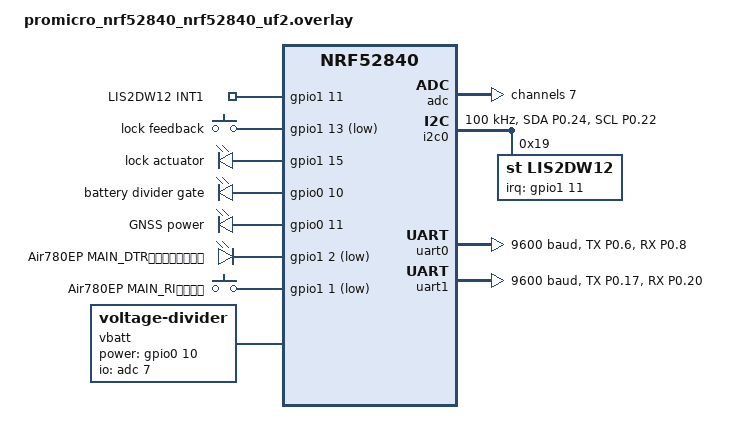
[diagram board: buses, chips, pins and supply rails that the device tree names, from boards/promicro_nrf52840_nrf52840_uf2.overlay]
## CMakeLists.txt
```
# 电瓶车定位固件（nRF52840 / NCS-Zephyr）
#
# ⚠ 本文件在写入时**没有被编译验证过** —— 这台机器上没有 NCS/Zephyr SDK，
#    也没有任何 C 编译器（`gcc: command not found`）。语法与 API 用法是按
#    DESIGN.md 里已核实的符号名写的，但**第一次 `west build` 一定会有编译错误**。
#    见 docs/FIRMWARE.md 的「怎么编译」一节。

cmake_minimum_required(VERSION 3.20.0)

find_package(Zephyr REQUIRED HINTS $ENV{ZEPHYR_BASE})
project(ebike_tracker C)

target_sources(app PRIVATE
    src/main.c
    src/proto.c
    src/nvstore.c
    src/crypto.c
    src/unlock.c
    src/ble_unlock.c
    src/motion.c
    src/battery.c
    src/lock.c
    src/gnss.c
    src/modem.c
    src/uplink.c
)

target_include_directories(app PRIVATE src)
```

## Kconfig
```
menu "电瓶车定位固件"

config EBIKE_DEVICE_ID
	string "设备 id（等于 MQTT 用户名，出现在 topic 层级里）"
	default "bike01"
	help
	  必须匹配 [a-z0-9-]{1,32}，且服务端配置里要有同名设备。
	  契约 §4：id 在 topic 层级里，ACL 靠前缀隔离。

config EBIKE_FW_VERSION
	string "固件版本（上报在 up/hello 的 fw 字段）"
	default "0.1.0"

config EBIKE_MQTT_HOST
	string "MQTT 服务端主机名或 IP"
	default "192.168.1.10"
	help
	  必须与服务端证书的 CN 一致 —— 模组的 AT+SSLCFG="hostname" 会校验它。
	  填错的话设备侧只会看到一个 ERROR，隔着 9600 baud 极难诊断。

config EBIKE_MQTT_PORT
	int "MQTT 端口"
	default 8883

config EBIKE_MQTT_PASSWORD
	string "MQTT 口令"
	default ""
	help
	  由服务端的 `ebike-server init` 生成，只显示一次。
	  ⚠ 这个值会明文进固件二进制。设备装在车上，拆开就能读 flash
	  （DESIGN.md §5.4 第 1 条已承认这个攻击面），所以它和客户端证书
	  私钥的安全等级一样 —— 这正是契约 §2 决定不做 mTLS 的理由。

config EBIKE_REPORT_INTERVAL
	int "默认上报周期（秒）"
	default 900
	help
	  服务端的离线判定 = 本值 × 3 + 120（契约 §4.2），
	  改这里要同时改服务端配置的 report_interval。

config EBIKE_MOTION_THRESHOLD_MG
	int "运动唤醒阈值（mg）"
	default 150
	range 31 2000
	help
	  LIS2DW12 的 WAKE_UP_THS 一格 = 31.25 mg（±2 g 量程）。
	  电瓶车从 100~200 mg 起调（DESIGN.md §3.7）。
	  阈值只能运行时设，不是 DTS 属性。

config EBIKE_STILL_AFTER_S
	int "多久没有运动事件就判静止（秒）"
	default 30
	range 5 600
	help
	  软件静止判定的超时。**硬件的 STATIONARY 事件在本板上用不了**
	  （走 INT2，只接了 INT1），所以静止完全靠这个计时器 ——
	  详见 src/motion.h 的长注释。

	  必须明显小于 main.c 的 IDLE_AFTER_STILL_MS（5 分钟，关广播的门槛）：
	  前者判「不动了」，后者判「不动够久了」。设得比它大的话关广播的条件
	  永远等不到。motion.c 里有 BUILD_ASSERT 钉这一条。

	  30 秒的取值：等红灯、推车挪位这类停顿不该立刻判成静止，
	  但也不能久到让「车被搬走后又静止了」这个事件迟迟不上报。

config EBIKE_LOW_VOLT_1
	int "第一欠压阈值（毫伏）"
	default 46000
	help
	  跨过就降低上报频率并报 lowbatt lv=1（DESIGN.md §6）。
	  具体值依赖实际电池组的 BMS 截止点，采购后实测确定。

config EBIKE_LOW_VOLT_2
	int "第二欠压阈值（毫伏）"
	default 44000
	help
	  跨过就停止周期上报，只保留手机 BLE 开锁（那条路完全离线，不吃车电池
	  的通信开销）。运动事件仍然会触发一次上报 —— 车在这个电量下被动了，
	  比省那点电重要。

config EBIKE_LOW_VOLT_3
	int "第三欠压阈值（毫伏）"
	default 42000
	help
	  跨过就主动进 System OFF，只留运动唤醒（DESIGN.md §6 第 4 级）。
	  这一级是保护**车电池**不被抽空，不是保护设备自己（设备没有独立电源）。
	  42 V 是 48 V 铅酸 12 节 × 1.75 V/节 的物理底线；锂电要按 BMS 截止点改。
	  必须 < LOW_VOLT_2，否则第 2 级永远不会生效。

config EBIKE_ALLOW_REMOTE_UNLOCK
	bool "接受下行的 unlock 指令"
	default n
	help
	  远程开锁绕过 §5.2 的挑战应答，信的只是 MQTT 那层的 TLS + 口令。
	  服务端侧默认也是关的（契约 §6.1），两边都要打开才生效。

config EBIKE_LOG_LEVEL
	int "本项目模块的日志等级"
	default 3
	range 0 4

endmenu

source "Kconfig.zephyr"
```

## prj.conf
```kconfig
# nRF52840 ProMicro 克隆板 —— 电瓶车定位 + 手机 BLE 开锁
#
# 符号名的两处更正来自 DESIGN.md §2.2，原稿写错过：
#   CONFIG_PSA_WANT_KEY_TYPE_HMAC（不是 KEY_TYPE_AES）
# DTS 里的 irq-gpios（不是 int1-gpios）见 overlay。

# --- 板级 / 构建 ---------------------------------------------------------------
# 板子自带 Adafruit bootloader，**不要用 MCUboot**（DESIGN.md §3.4：会打架）
CONFIG_USE_DT_CODE_PARTITION=y
CONFIG_BUILD_OUTPUT_UF2=y

# --- BLE（GATT peripheral，开锁通道） -----------------------------------------
# 手机当 central 写 APDU，车回 notify —— DESIGN.md §2.1。
# 只做 peripheral：本设备从不主动扫描或发起连接。
CONFIG_BT=y
CONFIG_BT_PERIPHERAL=y
CONFIG_BT_MAX_CONN=1
CONFIG_BT_DEVICE_NAME="ebike"

# **不开 SMP、不开 BT_SETTINGS**，这是有意的（DESIGN.md §5.5 / ADR-004 §5）：
# 设备没有屏幕也没有键盘，IO capability 只能是 NoInputNoOutput，
# 那种配置下 LESC 只能走 Just Works —— 没有 MITM 防护（host/smp.c 的
# remote_sec_level_reachable() 对 JUST_WORKS 直接返回 AUTH_REQUIREMENTS，
# L3/L4 达不到）。认证由 §5.2 的 HMAC 挑战应答负责，不依赖链路加密。
# 不开 SMP ⇒ 没有 LTK/IRK 要持久化 ⇒ 不该让 BT 去写 counter 住的那 32 kB
# storage 分区（BT_SETTINGS 还会让 settings_load 多一处时序要求）。
CONFIG_BT_SMP=n
CONFIG_BT_SETTINGS=n

# MTU 必须调大，默认值差得不止一点：
#   ATT_MTU 默认 23（host/att_internal.h 的 BT_ATT_DEFAULT_LE_MTU），
#   写请求可写载荷 = ATT_MTU − 3（1 B opcode + 2 B handle）= 20 字节，
#   而最长一条 C-APDU 是 UNLOCK：5 + [uid(4)+counter(4)+mac(16)] + 1 = 30 字节。
# 本地上限由两者取小决定（att_internal.h：MIN(BT_L2CAP_RX_MTU, BT_L2CAP_TX_MTU)，
# 其中 BT_L2CAP_RX_MTU = CONFIG_BT_BUF_ACL_RX_SIZE − 4），所以两个都要给：
#   40 − 3 = 37 ≥ 30 ✓        44 − 4 = 40 ≥ 40 ✓
# ⚠ 副作用：ACL_RX_SIZE > 27 会让 BT_DATA_LEN_UPDATE 变成 default y，
#   进而 BT_CTLR_DATA_LENGTH=y，SDC 的 per-link 缓冲跟着涨。这是划算的 ——
#   换掉的是应用层分包逻辑，而分包会让「nonce 一次性」的安全论证被半条报文复杂化。
# ⚠ 手机侧仍要主动 requestMtu()：MTU 交换由 central 发起，我们是 server，
#   CONFIG_BT_GATT_AUTO_UPDATE_MTU 只对 GATT client 有效。
CONFIG_BT_L2CAP_TX_MTU=40
CONFIG_BT_BUF_ACL_RX_SIZE=44

# --- 密码学（CryptoCell-310 硬件 HMAC） ----------------------------------------
CONFIG_PSA_CRYPTO=y
CONFIG_PSA_WANT_GENERATE_RANDOM=y
CONFIG_PSA_WANT_ALG_HMAC=y
CONFIG_PSA_WANT_ALG_SHA_256=y
CONFIG_PSA_WANT_KEY_TYPE_HMAC=y
CONFIG_PSA_CRYPTO_DRIVER_CC3XX=y

# --- 持久化（密钥、counter、序号 q） -------------------------------------------
# counter 掉电必须不回零，否则 §5.2 的重放防护失效
CONFIG_SETTINGS=y
CONFIG_SETTINGS_NVS=y
CONFIG_NVS=y
CONFIG_FLASH=y
CONFIG_FLASH_MAP=y
CONFIG_FLASH_PAGE_LAYOUT=y

# --- 传感器 -------------------------------------------------------------------
CONFIG_SENSOR=y
CONFIG_LIS2DW12=y
CONFIG_LIS2DW12_TRIGGER_OWN_THREAD=y
CONFIG_LIS2DW12_THREAD_STACK_SIZE=1024

# `CONFIG_LIS2DW12_WAKEUP` 必须开，它 gate 了两样东西：
#   1. `SENSOR_TRIG_MOTION`（驱动的 `case SENSOR_TRIG_MOTION` 整段裹在
#      `#ifdef CONFIG_LIS2DW12_WAKEUP` 里，不开的话 sensor_trigger_set
#      返回 -ENOTSUP，motion_init 直接失败 —— **唤醒源根本不存在**）；
#   2. `SENSOR_ATTR_UPPER_THRESH`（lis2dw12.c:322 的
#      `#if (CONFIG_LIS2DW12_SLEEP || CONFIG_LIS2DW12_WAKEUP)`）—— 是 `||`，
#      所以单开 WAKEUP 就够，阈值照样能设。
CONFIG_LIS2DW12_WAKEUP=y

# ⚠ **`CONFIG_LIS2DW12_SLEEP` 刻意不开**（原来是 `=y`）。
# 它只 gate `SENSOR_TRIG_STATIONARY`，而那个触发走 **INT2**，本板只接了 INT1
# —— 注册它会返回 0 但事件永不到达（src/motion.h 的长注释）。
# 静止判定已改成 motion.c 里的软件计时（`CONFIG_EBIKE_STILL_AFTER_S`），
# 代码里不再注册 STATIONARY，所以这个符号是纯负担：
# 多编一段 ISR 分支、多一个 handler 指针、还让读配置的人以为硬件静止检测可用。

CONFIG_I2C=y
CONFIG_ADC=y
CONFIG_GPIO=y

# ⚠ **必须显式关掉。** overlay 里 `vbatt` 节点的 compatible 是 "voltage-divider"，
# 而 `drivers/sensor/voltage_divider/Kconfig` 是 `default y` +
# `depends on DT_HAS_VOLTAGE_DIVIDER_ENABLED` —— 只要节点存在它就会被编进来。
#
# 那个驱动会成为 `power-gpios`（= batt_gate）的**第二个占有者**，而且默认状态相反：
# `voltage_init()` 结尾的 `pm_device_driver_init()` 在 PM_DEVICE=y /
# PM_DEVICE_RUNTIME=n 下会依次跑 TURN_ON → **RESUME**，RESUME 里
# `gpio_pin_set_dt(&config->gpio_power, 1)` 把门控**打开并一直留着**。
# 现在只是因为 `battery_init()` 在 application 阶段跑得更晚、又把它拉回低
# 才没事 —— 依赖初始化顺序的巧合，不是设计。
#
# battery.c 用到的两样东西都不需要这个驱动：
#   VOLTAGE_DIVIDER_DT_SPEC_GET  —— 纯 DT 宏
#   voltage_divider_scale_dt()   —— 头文件里的 static inline
# 所以关掉它没有任何损失，只去掉一个会偷偷开门控的所有者。
CONFIG_VOLTAGE_DIVIDER=n

# --- 串口（GNSS + Air780EP） ---------------------------------------------------
CONFIG_SERIAL=y
CONFIG_UART_INTERRUPT_DRIVEN=y
CONFIG_UART_ASYNC_API=n
CONFIG_RING_BUFFER=y

# --- 低功耗 -------------------------------------------------------------------
# System OFF 0.40 µA / System ON+RTC 3.16 µA（DESIGN.md §4.2）
#
# ⚠ **不要加 CONFIG_PM=y。** `subsys/pm/Kconfig` 的 `config PM` 要求
# `depends on SYS_CLOCK_EXISTS && HAS_PM`，而 `soc/nordic/nrf52/Kconfig` 只
# `select HAS_POWEROFF`，**没有 HAS_PM**（整棵树里 select HAS_PM 的只有
# nrf54h / nrf92）。写了会是未满足依赖的 Kconfig warning，而 Zephyr 的
# `scripts/kconfig/kconfig.py` 把这类 warning 升级成 error。
# 上游的 `samples/boards/nordic/system_off` 也只开 PM_DEVICE + POWEROFF。
CONFIG_PM_DEVICE=y
CONFIG_POWEROFF=y

# --- 日志：走 RTT，不走 UART/USB ------------------------------------------------
# 板级默认（`boards/common/usb/Kconfig.cdc_acm_serial.defconfig`）会把 console
# 挂到 **USB CDC ACM**（`cdc_acm_serial.dtsi` 里 `zephyr,console = &board_cdc_acm_uart`），
# 并且 `CDC_ACM_SERIAL_INITIALIZE_AT_BOOT` 默认 y —— 那意味着开机就起 USB 栈。
# 电池产品不能这样：USB 外设常开是毫安级，而且本设计的 USB 口根本不引出（§5.9）。
#
# 所以关掉板级 CDC ACM 后端，改用 RTT：RTT 在没接调试器时不产生额外功耗，
# 而 J-Link 仍然是这块克隆板的调试主路（板载 bootloader 只给 UF2 烧写，
# 单步和实时日志都要 SWD）。
# 顺带解掉一个隐患：console 若落到 uart0，会和 GNSS 抢同一个外设。
CONFIG_BOARD_SERIAL_BACKEND_CDC_ACM=n
CONFIG_USE_SEGGER_RTT=y
CONFIG_RTT_CONSOLE=y
CONFIG_UART_CONSOLE=n
CONFIG_CONSOLE=y
CONFIG_LOG=y
CONFIG_LOG_MODE_DEFERRED=y
CONFIG_LOG_BACKEND_RTT=y
CONFIG_LOG_DEFAULT_LEVEL=3

# --- 其它 ---------------------------------------------------------------------
CONFIG_MAIN_STACK_SIZE=4096
CONFIG_REBOOT=y
# 复位原因 → 契约 §5.1 的 rst 五值闭集（uplink.c 的 reset_cause_str）。
# ⚠ `CONFIG_HWINFO` 这一行**必须有**：`drivers/hwinfo/Kconfig.nrf` 是
# rsource 在 `if HWINFO` 里的，所以 `HWINFO_NRF` 的那个 `default y`
# 只有在 HWINFO 打开之后才生效。少这一行是链接期
# `undefined reference to z_impl_hwinfo_get_reset_cause`（实测过）。
CONFIG_HWINFO=y
CONFIG_JSON_LIBRARY=n
# proto.c 用 base64_decode() 解 dn/secret 的 32 字节密钥（契约 §6.2）。
# 这个符号默认 n，不开就是链接期 `undefined reference to base64_decode`（实测过）。
CONFIG_BASE64=y
# proto.c 用 %.6f / %.1f 拼报文，没有它坐标会变成乱码
CONFIG_CBPRINTF_FP_SUPPORT=y
```

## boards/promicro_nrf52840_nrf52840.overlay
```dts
/*
 * 板级 overlay：nRF52840 ProMicro 克隆板。
 *
 * ⚠ 两处必须自己确认的（DESIGN.md §3.4 / §3.5）：
 *
 * 1. **pinctrl 冲突**：上游 promicro_nrf52840-pinctrl.dtsi 的 uart0 是
 *    TX=P0.09 / RX=P0.10，而这两个脚是 NFC1/NFC2。下面把 uart0 挪到
 *    P0.06/P0.08，并新开 uart1 给 Air780EP。**引脚号是按 J2/J4 的可用脚挑的，
 *    实物到手要对着板子核一遍。**
 *
 * 2. **GPIO 余量是 19 个**（21 可用 − NFCT 占 2）。下面用掉 17 个。
 *    如果锁要 3 根线，就是 19/19 零余量，INT2 那根潜在的第二中断线没地方接。
 */

/ {
	aliases {
		/* ⚠ **只保留真正被 DT_ALIAS 取用的那一个。**
		 * 其余六个（lock-drive / lock-sense / batt-gate / gnss-power /
		 * modem-pwrkey / modem-ri）删掉了：所有 .c 文件一律用
		 * `DT_NODELABEL(...)`，那些别名是纯装饰，留着只会让人以为
		 * 换引脚时改别名就够了。
		 *
		 * `motion-int` 留着是因为 main.c 的 `enter_system_off()` 用
		 * `DT_ALIAS(motion_int)` 拿这根线 —— 它要绕过 LIS2DW12 驱动
		 * 自己把触发方式从边沿改成 level sense（GPIOTE 在 System OFF
		 * 下断电，只有 SENSE→DETECT 能唤醒）。 */
		motion-int = &motion_int;
	};

	ebike_gpios {
		compatible = "gpio-keys";

		/* LIS2DW12 INT1。
		 * ⚠ **这个节点和 `&lis2dw12` 的 `irq-gpios` 是同一根物理线**
		 * （都是 P1.11）。两处声明是故意的、也是必需的：
		 * 传感器驱动按边沿触发配它（`GPIO_INT_EDGE_TO_ACTIVE`），
		 * 而进 System OFF 前应用层必须把它重配成 level sense
		 * （见 main.c 的 `enter_system_off()`）—— 那需要一个
		 * 独立于传感器驱动的 `gpio_dt_spec`，就是这个节点。
		 *
		 * `gpio-keys` 只是借用一个通用的 GPIO 容器 binding；
		 * `CONFIG_GPIO_KEYS` 没开，所以上游 gpio_keys 驱动不会实例化它。
		 *
		 * 传感器侧必须配成推挽高有效 —— 开漏+上拉会让引脚停在
		 * VIL/VIH 之间，nRF52840 手册明确说那会增加电流（DESIGN.md §3.7），
		 * 而且悬空电平会让 level sense 反复自触发。 */
		motion_int: motion_int {
			gpios = <&gpio1 11 (GPIO_ACTIVE_HIGH | GPIO_PULL_DOWN)>;
			label = "LIS2DW12 INT1";
		};

		/* 锁位置反馈微动开关 */
		lock_sense: lock_sense {
			gpios = <&gpio1 13 (GPIO_ACTIVE_LOW | GPIO_PULL_UP)>;
			label = "lock feedback";
		};
	};

	ebike_outputs {
		compatible = "gpio-leds";

		/* 锁驱动。电磁锁 vs 电机锁还没定（DESIGN.md §7 第 1 条），
		 * 这里按「一根线，高有效，脉冲驱动」写，定了之后可能要改成半桥两根线。 */
		lock_drive: lock_drive {
			gpios = <&gpio1 15 GPIO_ACTIVE_HIGH>;
			label = "lock actuator";
		};

		/* 电池采样分压的门控 MOSFET。1M+1M 分压对 58.8V 是 29 µA 常流，
		 * 比整机静态电流大一个量级，所以只在测的瞬间开（DESIGN.md §3.6）。 */
		batt_gate: batt_gate {
			gpios = <&gpio0 4 GPIO_ACTIVE_HIGH>;
			label = "battery divider gate";
		};

		/* GNSS 电源门控。开关管型号未定（DESIGN.md §7.2）。 */
		gnss_power: gnss_power {
			gpios = <&gpio0 11 GPIO_ACTIVE_HIGH>;
			label = "GNSS power";
		};

		/* Air780EP PWRKEY：开集拉低 >1 s 开机。
		 * ⚠ 模组内部已有 5.6k 上拉，**不要外加上拉**（DESIGN.md §8.1）。
		 * 模组上电不自启动，所以这根线是必须的。 */
		modem_pwrkey: modem_pwrkey {
			gpios = <&gpio0 12 GPIO_ACTIVE_LOW>;
			label = "Air780EP PWRKEY";
		};
	};

	ebike_inputs {
		compatible = "gpio-keys";

		/* MAIN_RI：AT+CFGRI=1 之后出 120 ms 低脉冲。
		 * ⚠ 必须配 AT^WAKEUPHEX 把 RI 限定到魔术下行串，否则每条例行 URC
		 * 都会把主控从 System OFF 拽出来，功耗预算直接崩（DESIGN.md §8.3）。
		 * ⚠⚠ 这两条命令在 AT 固件 V1011 上能不能用**未核实**（§8.7），
		 * R0 阶段用一根 UART 线先验。
		 *
		 * ⚠⚠⚠ **两件事都还没落地，这个节点目前只是声明**：
		 * 1. P0.26 是**占位脚号**（DESIGN.md §11 #18）。真实的 MAIN_RI
		 *    脚号至今无来源（`docs.openluat.com/4Gmodulepin/` 404），
		 *    **布板前必须查 `Air780EP硬件手册V1.1.pdf`**。
		 * 2. **没有任何 C 代码取用它**（全 src 搜 `modem_ri` 只有这里）。
		 *    modem.c 发了 `AT+CFGRI=1`，但主控侧没人监听这根线 ——
		 *    「模组主动唤醒主控」这条链目前是半条。
		 *    定完脚号之后还要写监听代码。 */
		modem_ri: modem_ri {
			gpios = <&gpio0 26 (GPIO_ACTIVE_LOW | GPIO_PULL_UP)>;
			label = "Air780EP MAIN_RI (占位脚号，无代码取用)";
		};
	};

	/* 电池电压采样。ADC 只有 3 个真脚（DESIGN.md §3.5）：
	 * P0.02(AIN0) / P0.29(AIN5) / P0.31(AIN7)。用 P0.31。
	 * ZMK 的 A6~A10 别名不是 SAADC 通道，别当模拟脚用。 */
	vbatt: vbatt {
		compatible = "voltage-divider";
		io-channels = <&adc 7>;
		output-ohms = <1000000>;
		full-ohms = <2000000>;
		power-gpios = <&gpio0 4 GPIO_ACTIVE_HIGH>;
	};
};

&adc {
	status = "okay";
	#address-cells = <1>;
	#size-cells = <0>;

	channel@7 {
		reg = <7>;
		zephyr,gain = "ADC_GAIN_1_6";
		zephyr,reference = "ADC_REF_INTERNAL";
		zephyr,acquisition-time = <ADC_ACQ_TIME(ADC_ACQ_TIME_MICROSECONDS, 40)>;
		zephyr,input-positive = <NRF_SAADC_AIN7>;
		zephyr,resolution = <12>;
	};
};

/* --- I2C：LIS2DW12 ---------------------------------------------------------
 * 地址 0x19 要求 SA0/SDO 接 VDD_IO。
 * ⚠ SA0 接地的话内部 20.4~54.4 kΩ 上拉会白烧 110~160 µA（DESIGN.md §3.7）。
 */
&i2c0 {
	status = "okay";
	compatible = "nordic,nrf-twim";
	clock-frequency = <I2C_BITRATE_STANDARD>;
	pinctrl-0 = <&i2c0_default>;
	pinctrl-1 = <&i2c0_sleep>;
	pinctrl-names = "default", "sleep";

	lis2dw12: lis2dw12@19 {
		compatible = "st,lis2dw12";
		reg = <0x19>;
		irq-gpios = <&gpio1 11 GPIO_ACTIVE_HIGH>;   /* 属性名是 irq-gpios */
		int-pin = <1>;
		odr = <12>;                  /* 12.5 Hz → 1 µA @LP mode 1 */
		range = <2>;                 /* ±2 g，阈值一格 31.25 mg */
		power-mode = <LIS2DW12_DT_LP_M1>;
		wakeup-duration = <LIS2DW12_DT_WAKEUP_2_ODR>;
	};
};

/* --- UART0：GNSS（ATGM336H-5N，NMEA 9600） --------------------------------- */
&uart0 {
	status = "okay";
	current-speed = <9600>;
	pinctrl-0 = <&uart0_default>;
	pinctrl-1 = <&uart0_sleep>;
	pinctrl-names = "default", "sleep";
};

/* --- UART1：Air780EP AT 链路 -----------------------------------------------
 * 9600 锁死：AT+IPR 默认自适应太脆，而两种低功耗模式都要求 9600
 * 才能可靠唤醒（DESIGN.md §8.1）。出厂 AT+IPR=9600;&W 设一次。
 */
&uart1 {
	status = "okay";
	current-speed = <9600>;
	pinctrl-0 = <&uart1_default>;
	pinctrl-1 = <&uart1_sleep>;
	pinctrl-names = "default", "sleep";
};

&pinctrl {
	/* ⚠ 把 uart0 从 P0.09/P0.10 挪开 —— 那两个脚给 NFCT 了。
	 * 上游 promicro_nrf52840-pinctrl.dtsi 的默认值会和 NFC 撞（DESIGN.md §3.4）。 */
	uart0_default: uart0_default {
		group1 {
			psels = <NRF_PSEL(UART_TX, 0, 6)>;
		};
		group2 {
			psels = <NRF_PSEL(UART_RX, 0, 8)>;
			bias-pull-up;
		};
	};

	uart0_sleep: uart0_sleep {
		group1 {
			psels = <NRF_PSEL(UART_TX, 0, 6)>,
				<NRF_PSEL(UART_RX, 0, 8)>;
			low-power-enable;
		};
	};

	uart1_default: uart1_default {
		group1 {
			psels = <NRF_PSEL(UART_TX, 0, 17)>;
		};
		group2 {
			psels = <NRF_PSEL(UART_RX, 0, 20)>;
			bias-pull-up;
		};
	};

	uart1_sleep: uart1_sleep {
		group1 {
			psels = <NRF_PSEL(UART_TX, 0, 17)>,
				<NRF_PSEL(UART_RX, 0, 20)>;
			low-power-enable;
		};
	};

	i2c0_default: i2c0_default {
		group1 {
			psels = <NRF_PSEL(TWIM_SDA, 0, 24)>,
				<NRF_PSEL(TWIM_SCL, 0, 22)>;
		};
	};

	i2c0_sleep: i2c0_sleep {
		group1 {
			psels = <NRF_PSEL(TWIM_SDA, 0, 24)>,
				<NRF_PSEL(TWIM_SCL, 0, 22)>;
			low-power-enable;
		};
	};
};

/* SPI1 在 ZMK 的默认 pinctrl 里把 MOSI 放在 P0.10 —— 和 NFC2 撞，关掉。 */
&spi1 {
	status = "disabled";
};
```

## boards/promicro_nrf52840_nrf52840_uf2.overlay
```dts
/*
 * 板级 overlay：nRF52840 ProMicro 克隆板。
 *
 * ⚠ 三件必须对着实物/netlist 核的事（DESIGN.md §3.4 / §3.5）：
 *
 * 1. **只能用引出到排针的脚。** SoC 有 48 个 GPIO，这块板子只把 **21 个**
 *    引到焊盘，其余的**只到芯片焊盘、哪儿都不通** —— 而 devicetree 对此
 *    一无所知，填一个没引出的脚**编译照过**，直到接线时才发现没地方接。
 *    这个坑已经踩过三次（P0.04 门控、P0.12 PWRKEY、P0.26 RI，都在
 *    2026-09-04 从 `sasodoma/nrf52840-promicro` 的 netlist 逐脚复核时抓到）。
 *
 *    **引出脚白名单**（逐个 pad 追 net → 元件焊盘数出来的）：
 *      J2 十个：P0.06 P0.08 P0.17 P0.20 P0.22 P0.24 P1.00 P0.11 P1.04 P1.06
 *      J3 八个：P0.09 P0.10 P1.11 P1.13 P1.15 P0.02 P0.29 P0.31
 *      J4 三个：P1.01 P1.02 P1.07
 *    板内占用不引出：P0.00/P0.01（Y2 晶振）、P0.13（ME6217 CE）、P0.15（蓝 LED）。
 *    J3 第 10 个焊盘是 RESET（UICR.PSELRESET = P0.18），不能当 GPIO 用。
 *    `server/tests/test_firmware_contract.py` 把这份白名单钉成断言。
 *
 * 2. **pinctrl 冲突**：上游 promicro_nrf52840-pinctrl.dtsi 的 uart0 是
 *    TX=P0.09 / RX=P0.10。下面把 uart0 挪到 P0.06/P0.08，并新开 uart1
 *    给 Air780EP。
 *    （挪开的原始理由是 P0.09/P0.10 要给 NFCT；开锁改走 BLE 之后那两个脚
 *    自由了，其中 P0.10 现在给了 `batt_gate`，P0.09 是余量。）
 *
 * 3. **上游板级 DTS 会悄悄抢走排针脚**，文件末尾统一关掉：
 *    `i2c1`（P1.04/P1.06 = J2.12/J2.13）、`spi2`（P1.01/P1.02/P1.07 = 整个 J4）。
 *    i2c1 尤其阴险：`CONFIG_I2C_NRFX_TWIM=y` 让 twim1 真的实例化，
 *    `pm_device_driver_init()` 的 RESUME 会 `pinctrl_apply_state(DEFAULT)`，
 *    **开机就把那两个脚配成 I2C**（ELF 里 `__device_dts_ord_73` 实测存在）。
 *    ⚠ spi2 关掉这件事现在是**必需**而不是预防：`modem_ri`/`modem_dtr` 用了
 *    P1.01/P1.02，正是 spi2 的默认 SCK/MOSI。
 *
 * 用掉 14 个（下面逐个数），余 7 个：P0.02 P0.09 P0.29 P1.00 P1.04 P1.06 P1.07。
 * 锁要 3 根线、INT2 那根第二中断线都装得下。
 *
 * 2026-09-04 第二次改动（PWRKEY 已在硬件上接地）：
 *   `modem_pwrkey` P1.00 → **节点删除**（驱动一个已接地的脚 = 短路，见下面
 *   那段长注释）；新增 `modem_ri` P1.01（直连）、`modem_dtr` P1.02（开漏）。
 *   净变化：用掉的脚 13 → 14，P1.00 回到余量池。
 */

/* `power-mode` / `wakeup-duration` 用的是 LIS2DW12 的 dt-bindings 宏，
 * 而板级 DTS 不会带进这个头 —— 不显式 include 就是一个
 * 「expected number or parenthesized expression」的 devicetree parse error。
 * 其余宏（GPIO_ACTIVE_*、NRF_PSEL、NRF_SAADC_*、I2C_BITRATE_*）由
 * 板级 DTS / SoC dtsi 一路带进来，不用再 include。 */
#include <zephyr/dt-bindings/sensor/lis2dw12.h>

/ {
	aliases {
		/* ⚠ **只保留真正被 DT_ALIAS 取用的那一个。**
		 * 其余五个（lock-drive / lock-sense / batt-gate / gnss-power /
		 * modem-dtr）删掉了：所有 .c 文件一律用
		 * `DT_NODELABEL(...)`，那些别名是纯装饰，留着只会让人以为
		 * 换引脚时改别名就够了。
		 *
		 * `motion-int` 留着是因为 main.c 的 `enter_system_off()` 用
		 * `DT_ALIAS(motion_int)` 拿这根线 —— 它要绕过 LIS2DW12 驱动
		 * 自己把触发方式从边沿改成 level sense（GPIOTE 在 System OFF
		 * 下断电，只有 SENSE→DETECT 能唤醒）。 */
		motion-int = &motion_int;
	};

	ebike_gpios {
		compatible = "gpio-keys";

		/* LIS2DW12 INT1。
		 * ⚠ **这个节点和 `&lis2dw12` 的 `irq-gpios` 是同一根物理线**
		 * （都是 P1.11）。两处声明是故意的、也是必需的：
		 * 传感器驱动按边沿触发配它（`GPIO_INT_EDGE_TO_ACTIVE`），
		 * 而进 System OFF 前应用层必须把它重配成 level sense
		 * （见 main.c 的 `enter_system_off()`）—— 那需要一个
		 * 独立于传感器驱动的 `gpio_dt_spec`，就是这个节点。
		 *
		 * `gpio-keys` 只是借用一个通用的 GPIO 容器 binding；
		 * `CONFIG_GPIO_KEYS` 没开，所以上游 gpio_keys 驱动不会实例化它。
		 *
		 * 传感器侧必须配成推挽高有效 —— 开漏+上拉会让引脚停在
		 * VIL/VIH 之间，nRF52840 手册明确说那会增加电流（DESIGN.md §3.7），
		 * 而且悬空电平会让 level sense 反复自触发。 */
		motion_int: motion_int {
			gpios = <&gpio1 11 (GPIO_ACTIVE_HIGH | GPIO_PULL_DOWN)>;
			label = "LIS2DW12 INT1";
		};

		/* 锁位置反馈微动开关 */
		lock_sense: lock_sense {
			gpios = <&gpio1 13 (GPIO_ACTIVE_LOW | GPIO_PULL_UP)>;
			label = "lock feedback";
		};
	};

	ebike_outputs {
		compatible = "gpio-leds";

		/* 锁驱动。电磁锁 vs 电机锁还没定（DESIGN.md §7 第 1 条），
		 * 这里按「一根线，高有效，脉冲驱动」写，定了之后可能要改成半桥两根线。 */
		lock_drive: lock_drive {
			gpios = <&gpio1 15 GPIO_ACTIVE_HIGH>;
			label = "lock actuator";
		};

		/* 电池采样分压的门控 MOSFET。分压器常通是 5.96 µA @58.8 V
		 * （4.7M+4.7M/470k，见下面 vbatt 节点），和 nRF52840 自己
		 * GPIOTE PORT 的 2.36 µA 同一量级，所以只在测的瞬间开
		 * （DESIGN.md §3.6）。
		 *
		 * ⚠ **曾经填 P0.04，那个脚这块板没引出**（文件头 §1）。P0.04 大概
		 * 是从两处抄来的：正品 nice!nano 的 `BATIN/P0.04`，以及克隆板那份
		 * 画错的原理图 —— `archive/ADR-001 §5.6` 早就记了「R10/R11 铜箔
		 * 实际走到 P0.24 不是 P0.04」。而 P0.24 在本 overlay 里是 i2c0 SDA，
		 * 所以那两个 0201 焊盘**永远不要贴件**：贴上就是往 I2C 数据线上
		 * 挂一个分压器。
		 * 现在用 **P0.10 = J3.2**，和 ADC 脚 P0.31 同在 J3，走线短。
		 * 不占 P0.02/P0.29 是因为只有 3 个真 ADC 脚，别拿去做数字输出。 */
		batt_gate: batt_gate {
			gpios = <&gpio0 10 GPIO_ACTIVE_HIGH>;
			label = "battery divider gate";
		};

		/* GNSS 电源门控。开关管型号未定（DESIGN.md §7.2）。 */
		gnss_power: gnss_power {
			gpios = <&gpio0 11 GPIO_ACTIVE_HIGH>;
			label = "GNSS power";
		};

		/* Air780EP MAIN_DTR（PIN19）—— 主控 → 模组的唤醒 / 退出 PSM+。
		 *
		 * ⚠⚠ **必须开漏，绝不能推挽输出高。**
		 * DTR 配成 AGPIO 时在 LDO_AON 域，PIN100 接地后与主控同为 3.3 V，
		 * 所以「电平不匹配」这个前提消失了 —— 官方那条「Wakeup IO 不要
		 * 直连主控」的告警说的是 WAKEUP 类（LDO_1.8V 域，2 V 固定）。
		 * 但 AGPIOWU 还有一条独立约束：**单脚驱动能力只有 30 µA**
		 * （「由于切换电路的存在，作为 AGPIO 其每路的驱动能力也只有 30uA」）。
		 * 推挽输出高就是拿 3.3 V 域去顶一个 30 µA 的脚。
		 *
		 * `GPIO_OPEN_DRAIN` 只 sink 不 source：拉低靠 nRF，高电平靠模组
		 * 内部上拉。拉低电流由模组内部串的 5.6 kΩ 限住：
		 * 3.3 V / 5.6 kΩ ≈ 0.59 mA，nRF 的 sink 能力远超它。
		 * **外部不要再加任何上拉** —— 内部已经上拉到 LDO_AON。
		 *
		 * 极性：低有效（拉低=唤醒 / 退出 PSM+；释放成高=重进 PSM+）。
		 * `GPIO_ACTIVE_LOW` + `GPIO_OPEN_DRAIN` ⇒ 逻辑 1 = 物理低 = 拉低。
		 *
		 * 为什么是必需的而不是可选的：PWRKEY 已在硬件上接地（上电即开机、
		 * **无法关机**，UM1.0.7 §5.3.4.1.2），省电档只能走 PSM+，而退出 PSM+
		 * 的三条路是「拉低 DTR / 拉高 VBUS / 发 AT+POWERMODE="CLOSE"」——
		 * VBUS 本项目不接，命令那条要先用 UART 唤醒再发、多一个来回。
		 * DTR 是一次 GPIO 翻转就解决的那条。 */
		modem_dtr: modem_dtr {
			gpios = <&gpio1 2 (GPIO_ACTIVE_LOW | GPIO_OPEN_DRAIN)>;
			label = "Air780EP MAIN_DTR（开漏，只拉低）";
		};
	};

	ebike_inputs {
		compatible = "gpio-keys";

		/* Air780EP MAIN_RI（PIN20）—— 模组 → 主控的唯一通知线。
		 * 空闲高，有事出一个 **120 ms 低脉冲**。
		 *
		 * **可以直连，零外围器件。** 判据是电压域：
		 *   RI 的 Pad Name 是 `AGPIO4`（Air780EP_GPIO_table.pdf p1），
		 *   属 AGPIO 类而非 WAKEUP 类，电压域是 LDO_AON —— 而
		 *   「VDD_EXT 和 LDO_AON 都是通过 pm.ioVol() 设置输出电压，且对
		 *   二者同时进行修改，所有 IO 电平都同时修改且保持一致」。
		 * PIN100 已接地 ⇒ LDO_AON = 3.3 V ⇒ VOH = 0.8 × 3.3 = 2.64 V，
		 * 高于 nRF 的 VIH = 0.7 × 3.3 = 2.31 V，**余量 0.33 V**。
		 * （之前一版说「必须加三极管」是把 RI 当成了 WAKEUP 类 ——
		 * 那一类才是 LDO_1.8V 域的 2 V 固定电平，VOH 只有 1.6 V 打不动。）
		 *
		 * ⚠ 两条约束：
		 * 1. **单脚 ≤5 mA 且全部 AGPIO 合计 ≤5 mA**（LDO_AON 总 10 mA）。
		 *    nRF 输入是高阻，零问题 —— 但这根线上**不要挂分压电阻、LED、
		 *    外部上拉**。所以这里用 `GPIO_PULL_UP` 的**内部**上拉，
		 *    而不是外接电阻：空闲期模组已经驱动高，内部上拉只在模组侧
		 *    高阻（未开机/PSM+ 切换瞬间）时兜住电平，不额外耗 AGPIO 预算。
		 * 2. **上电或复位瞬间可能有 ~1 ms 异常高电平。** RI 是低有效脉冲，
		 *    毛刺方向无害（不会被误判成脉冲）。真在意可外加 10 kΩ 下拉，
		 *    但那会和内部上拉打架 —— 二选一，别都装。
		 *
		 * 走三极管方案会**反相**（模组低脉冲 → 主控看到高脉冲），直连没有
		 * 这个问题，所以中断沿就是 ACTIVE_LOW，和手册的「120 ms 低脉冲」一致。
		 *
		 * ⚠ `AT+CFGRI=1` 之后**每条例行 URC 都会出脉冲**，必须配
		 * `AT^WAKEUPHEX` 把它限定到魔术下行串，否则网络心跳会把主控
		 * 反复叫醒、功耗预算崩（§8.7 / §11 #17，那条命令的可用性仍未核实）。 */
		modem_ri: modem_ri {
			gpios = <&gpio1 1 (GPIO_ACTIVE_LOW | GPIO_PULL_UP)>;
			label = "Air780EP MAIN_RI（直连）";
		};
	};

	/* ⚠ **PWRKEY 没有节点，是故意的。**
	 *
	 * 硬件上 PWRKEY 已经**直接接地**（上电即开机）。手册对这种接法明写
	 * 「在上电开机模式下，**将无法关机**」（UM1.0.7 §5.3.4.1.2 p55）。
	 * 曾经有个 `modem_pwrkey` 节点（P1.00，ACTIVE_LOW），它必须删掉 ——
	 * 那个节点的 init 是 `GPIO_OUTPUT_INACTIVE`，ACTIVE_LOW 下 inactive
	 * = 物理**高**，接到已接地的 PWRKEY 上就是 nRF 的 GPIO 驱动 3.3 V
	 * 直接对地：**硬短路**。
	 *
	 * 连带的两处后果都已在 modem.c 里处理：
	 * - `power_on()` 不再触发开机，只轮询等模组自启后响应 AT；
	 * - 重连阶梯 3 级改用 `AT+CFUN=1,1`（软重启），不再 PWRKEY 硬关机。
	 */

	/* 电池电压采样。ADC 只有 3 个真脚（DESIGN.md §3.5）：
	 * P0.02(AIN0) / P0.29(AIN5) / P0.31(AIN7)。用 P0.31。
	 * ZMK 的 A6~A10 别名不是 SAADC 通道，别当模拟脚用。
	 *
	 * 分压比 **21:1** —— 上臂 4.7M + 4.7M 串联，下臂 470k。三个约束定的：
	 *
	 * 1. **引脚不能烧**。本板 REGOUT0=3V3 → VDD = 3.3 V 是工作上限
	 *    （nRF52840 PS v1.1 Table 172）；Table 173 的绝对最大是
	 *    VDD+0.3 = 3.6 V，但那是「短时暴露不永久损坏」，不是可用范围。
	 *    58.8 V / 21 = 2800 mV，1% 电阻最坏偏差下 2856 mV，余 444 mV。
	 *    要顶到 3.3 V 得电池到 68 V。
	 *    ⚠ 上一版是 1M/1M（2:1），58.8 V 会往 P0.31 灌 29.4 V —— **焊上就烧**。
	 * 2. **源阻抗 ≤ 800 kΩ**，否则下面那个 40 µs 采集时间不成立
	 *    （PS v1.1 §6.23.10.1 的 tACQ 表：10k→3 µs … 800k→40 µs）。
	 *    Rs = 9.4M ‖ 470k = 448 kΩ ✓。这条否掉了 20M/1M（Rs 952 kΩ 超标）。
	 * 3. **单只电阻的耐压**。上臂拆两只，每只只担 28 V。单只 15M 要担 56 V，
	 *    而 0603 厚膜的 Max. RCWV 是 75 V、0402 只有 50 V —— 余量太薄。
	 *    拆成两只之后封装随便选。
	 *
	 * 21:1 恰好整除（9.87M / 470k = 21），但代码不依赖这一点：
	 * battery.c 走 voltage_divider_scale_dt()（int64），非整数比例同样准。
	 *
	 * ⚠ 换电池规格必须重算 —— BUILD_ASSERT 的输入 `PACK_MAX_MV` 在 battery.c。 */
	vbatt: vbatt {
		compatible = "voltage-divider";
		io-channels = <&adc 7>;
		output-ohms = <470000>;
		full-ohms = <(4700000 + 4700000 + 470000)>;
		power-gpios = <&gpio0 10 GPIO_ACTIVE_HIGH>;
	};
};

&adc {
	status = "okay";
	#address-cells = <1>;
	#size-cells = <0>;

	/* gain 1/6 + 内部参考 600 mV → ADC 满量程 3600 mV
	 * （nrfx `ANALOG_REF_INTERNAL_VAL = 600`，非 nRF54 分支）。
	 * 注意满量程 3600 mV 只是**转换器**的上限，引脚的上限是 VDD = 3300 mV，
	 * 两者不是一回事 —— 分压比按 3300 mV 算，见 vbatt 节点第 1 条。
	 *
	 * 40 µs 采集时间对应源阻抗 ≤ 800 kΩ（PS v1.1 §6.23.10.1）。
	 * 本分压的 Rs = 448 kΩ，也满足 20 µs（≤400 kΩ）—— 但采样是几分钟
	 * 一次的事，多花 20 µs 换余量，不优化。 */
	channel@7 {
		reg = <7>;
		zephyr,gain = "ADC_GAIN_1_6";
		zephyr,reference = "ADC_REF_INTERNAL";
		zephyr,acquisition-time = <ADC_ACQ_TIME(ADC_ACQ_TIME_MICROSECONDS, 40)>;
		zephyr,input-positive = <NRF_SAADC_AIN7>;
		zephyr,resolution = <12>;
	};
};

/* --- I2C：LIS2DW12 ---------------------------------------------------------
 * 地址 0x19 要求 SA0/SDO 接 VDD_IO。
 * ⚠ SA0 接地的话内部 20.4~54.4 kΩ 上拉会白烧 110~160 µA（DESIGN.md §3.7）。
 *
 * ⚠ **不装外部上拉电阻**，用 nRF52840 的内部上拉（见下面 pinctrl 的
 * `bias-pull-up`）。因此 `clock-frequency` **必须留在 100 kHz** ——
 * 内部 RPU 最坏 16 kΩ，400 kHz 的 300 ns 上升时间要求总线电容 ≤ 22 pF，
 * 达不到。改快之前先装外部 2.2~4.7 kΩ。
 */
&i2c0 {
	status = "okay";
	compatible = "nordic,nrf-twim";
	clock-frequency = <I2C_BITRATE_STANDARD>;   /* 100 kHz，见上面第 2 条 */
	pinctrl-0 = <&i2c0_default>;
	pinctrl-1 = <&i2c0_sleep>;
	pinctrl-names = "default", "sleep";

	lis2dw12: lis2dw12@19 {
		compatible = "st,lis2dw12";
		reg = <0x19>;
		irq-gpios = <&gpio1 11 GPIO_ACTIVE_HIGH>;   /* 属性名是 irq-gpios */
		int-pin = <1>;
		odr = <12>;                  /* 12.5 Hz → 1 µA @LP mode 1 */
		range = <2>;                 /* ±2 g，阈值一格 31.25 mg */
		power-mode = <LIS2DW12_DT_LP_M1>;
		wakeup-duration = <LIS2DW12_DT_WAKEUP_2_ODR>;
	};
};

/* --- UART0：GNSS（ATGM336H-5N，NMEA 9600） --------------------------------- */
&uart0 {
	status = "okay";
	current-speed = <9600>;
	pinctrl-0 = <&uart0_default>;
	pinctrl-1 = <&uart0_sleep>;
	pinctrl-names = "default", "sleep";
};

/* --- UART1：Air780EP AT 链路 -----------------------------------------------
 * 9600 锁死：AT+IPR 默认自适应太脆，而两种低功耗模式都要求 9600
 * 才能可靠唤醒（DESIGN.md §8.1）。出厂 AT+IPR=9600;&W 设一次。
 */
&uart1 {
	status = "okay";
	current-speed = <9600>;
	pinctrl-0 = <&uart1_default>;
	pinctrl-1 = <&uart1_sleep>;
	pinctrl-names = "default", "sleep";
};

&pinctrl {
	/* ⚠ uart0 不能用上游默认的 P0.09/P0.10：那是本工程留出来的余量脚
	 * （原本给 NFCT，见文件头 §1），而且 SPI1 的默认 MOSI 也在 P0.10。
	 * 挪到 P0.06/P0.08（DESIGN.md §3.4）。 */
	uart0_default: uart0_default {
		group1 {
			psels = <NRF_PSEL(UART_TX, 0, 6)>;
		};
		group2 {
			psels = <NRF_PSEL(UART_RX, 0, 8)>;
			bias-pull-up;
		};
	};

	uart0_sleep: uart0_sleep {
		group1 {
			psels = <NRF_PSEL(UART_TX, 0, 6)>,
				<NRF_PSEL(UART_RX, 0, 8)>;
			low-power-enable;
		};
	};

	uart1_default: uart1_default {
		group1 {
			psels = <NRF_PSEL(UART_TX, 0, 17)>;
		};
		group2 {
			psels = <NRF_PSEL(UART_RX, 0, 20)>;
			bias-pull-up;
		};
	};

	uart1_sleep: uart1_sleep {
		group1 {
			psels = <NRF_PSEL(UART_TX, 0, 17)>,
				<NRF_PSEL(UART_RX, 0, 20)>;
			low-power-enable;
		};
	};

	/* ⚠ **`bias-pull-up` 这两行是 I2C 能不能通的前提，不是优化。**
	 *
	 * nrfx 的 `TWIM_PIN_INIT`（nrfx_twim.c:68）本来会给 SCL/SDA 配
	 * `NRF_GPIO_PIN_PULLUP`，但 Zephyr 的 twim 驱动传的是
	 * `skip_gpio_cfg = true` + `skip_psel_cfg = true`（i2c_nrfx_twim.c:306），
	 * 那段整个被跳过 —— **引脚配置完全由 pinctrl 决定**。
	 * 少了这两行，pincfg 的 pull 字段是 `NRF_PULL_NONE`（实测：`0x0C000018`
	 * / `0x0B000016`），两根线上内外都没有上拉，I2C 一个字节都传不出去。
	 * 加上之后是 `0x0C000618` / `0x0B000616`（pull=3=NRF_PULL_UP，
	 * 从 `__pinctrl_state_pins_0__device_dts_ord_*` 解出来核对过）。
	 *
	 * 用内部上拉（RPU 11/13/16 kΩ min/typ/max，PS v1.1 GPIO 电气规格）
	 * 换掉两只外部电阻，**代价是两条硬约束**：
	 *
	 * 1. **必须停在 100 kHz。** 上升时间 t_r = 0.847·R·C（30%→70%）：
	 *    16 kΩ 最坏 + 30 pF ≈ 407 ns，100 kHz 的 1000 ns 上限够；
	 *    400 kHz 只有 300 ns，要求 C ≤ 22 pF —— 做不到。
	 *    所以 `clock-frequency` 必须留在 `I2C_BITRATE_STANDARD`。
	 * 2. **总线电容 ≤ 74 pF**（16 kΩ 下正好 1000 ns）。短杜邦线挂一个
	 *    LIS2DW12 完全够（焊盘 3 pF + 传感器两脚约 20 pF + 线材几 pF）。
	 *    **再挂第二个 I2C 器件、或线拉到半米以上，余量就没了** —— 而 I2C
	 *    的临界失效很难看：偶发 NACK、偶发读到错值，不是干脆不通。
	 *    要扩展就装外部 2.2~4.7 kΩ 并把这两行删掉。
	 *
	 * 功耗上没有代价：上拉只在线被拉低时流 3.3 V / 13 kΩ = 254 µA，
	 * 而 I2C 空闲是高电平、几分钟才采样几百微秒，平均下来是皮安级。
	 */
	i2c0_default: i2c0_default {
		group1 {
			psels = <NRF_PSEL(TWIM_SDA, 0, 24)>,
				<NRF_PSEL(TWIM_SCL, 0, 22)>;
			bias-pull-up;
		};
	};

	/* sleep 态也要保留上拉。这个状态带 `low-power-enable`，pinctrl 会强制
	 * `dir=INPUT` + `input=DISCONNECT`，但 `NRF_GET_PULL` 照旧生效
	 * （pinctrl_nrf.c:586 那一次 `nrf_gpio_cfg`）。保留上拉让总线在休眠期间
	 * 停在高电平而不是悬空 —— `PIN_CNF` 是 retained 寄存器，System OFF
	 * 下也保持。悬空输入正是 §3.7 那条「电压停在 VIL/VIH 之间会增加电流」
	 * 想避免的情况。 */
	i2c0_sleep: i2c0_sleep {
		group1 {
			psels = <NRF_PSEL(TWIM_SDA, 0, 24)>,
				<NRF_PSEL(TWIM_SCL, 0, 22)>;
			bias-pull-up;
			low-power-enable;
		};
	};
};

/* --- 关掉上游板级 DTS 打开、但本工程不用的外设 ----------------------------------
 * 每一个都在抢排针脚（文件头 §3）。`status = "disabled"` 之后驱动不实例化，
 * pinctrl 也就不会在 init 时被应用。
 *
 * ⚠ pwm0（P0.15）**故意不关**：P0.15 是板载蓝 LED，不引出、不占排针脚，
 * 而 `pwmleds`/`mcuboot-led0` 那几个节点引用着它，关掉只增加风险不换来余量。
 */

/* i2c1 = P1.04/P1.06 = J2.12/J2.13。这个是真丢脚：CONFIG_I2C_NRFX_TWIM=y
 * 会让 twim1 实例化并在 init 里应用 pinctrl（文件头 §3）。 */
&i2c1 {
	status = "disabled";
};

/* spi2 = P1.01/P1.02/P1.07 = 整个 J4。当前 CONFIG_SPI 没开所以还没丢，
 * 但谁哪天开了 SPI 就会连带吃掉 J4 三个脚 —— 提前关掉。
 * 板级 aliases 里的 `spi = &spi2` 留着无害：没有代码 DEVICE_DT_GET 它。 */
&spi2 {
	status = "disabled";
};

/* spi1 在 SoC dtsi 里本来就是 disabled，这里显式写一遍是因为 ZMK 的
 * `spi1_default` 把 MOSI 放在 P0.10 —— 而 P0.10 现在是 `batt_gate`。
 * 将来若真把 BOARD_ROOT 换成 ZMK 的 nice_nano，这一行是那条冲突的护栏。 */
&spi1 {
	status = "disabled";
};
```

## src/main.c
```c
/*
 * 主流程。
 *
 * 状态机就三态，刻意保持简单 —— 复杂度全在 modem.c 和 unlock.c 里：
 *
 *   ACTIVE   刚被运动唤醒或刚开机。BLE 广播开着，定时上报。
 *   IDLE     静止一段时间了。广播关掉（**为了不可被扫描发现，不是为了省电** ——
 *            广播只有 16~130 µA，见 IDLE_AFTER_STILL_MS），
 *            只留运动中断和定时器。
 *   OFF      车电池跌破第三阈值（§6 第 4 级）。System OFF，只留运动唤醒；
 *            醒来等于一次复位。见文件末尾的说明。
 *
 * 唤醒源：LIS2DW12 INT1（运动）、定时器（周期上报）。
 * **BLE 不是唤醒源** —— radio 在 System OFF 下断电，手机连不上一台已关机的车；
 * 这和 NFC 场唤醒不同（那条路存在但没用，见 ADR-004 §3）。
 */

#include "battery.h"
#include "crypto.h"
#include "gnss.h"
#include "lock.h"
#include "modem.h"
#include "motion.h"
#include "ble_unlock.h"
#include "nvstore.h"
#include "proto.h"
#include "unlock.h"
#include "uplink.h"

#include <errno.h>
#include <stdio.h>

#include <zephyr/device.h>
#include <zephyr/drivers/gpio.h>
#include <zephyr/kernel.h>
#include <zephyr/logging/log.h>
#include <zephyr/pm/device.h>
#include <zephyr/sys/poweroff.h>

LOG_MODULE_REGISTER(main, CONFIG_EBIKE_LOG_LEVEL);

/* 静止多久之后关广播进 IDLE。5 分钟：够用户走开又回来（忘了东西）。
 *
 * ⚠ **这不是省电措施。** 广播本身 100~150 ms 间隔约 130 µA，1 s 间隔约 16 µA，
 * 都淹没在 4G 模组 500~1500 µA 的地板下面（ADR-004 §3）。关它的理由是
 * **不可被发现**：一台常年广播的车可以被沿街扫描长期跟踪、被枚举、被挑中。 */
#define IDLE_AFTER_STILL_MS (5 * 60 * 1000)

/* 两个门槛的关系必须成立，否则关广播的条件永远等不到：
 *   CONFIG_EBIKE_STILL_AFTER_S  判「不动了」        （motion.c 的软件计时）
 *   IDLE_AFTER_STILL_MS         判「不动够久了」    （下面关广播用）
 * 前者必须明显小于后者。这条在 motion.h 里也写了，这里是可执行的那一份。 */
BUILD_ASSERT(CONFIG_EBIKE_STILL_AFTER_S * 1000 < IDLE_AFTER_STILL_MS,
	     "EBIKE_STILL_AFTER_S must be well below IDLE_AFTER_STILL_MS, "
	     "otherwise the advertising-off condition can never be reached.");

/* 进 System OFF 前要武装的唤醒脚，以及要 suspend 的外设。
 * `motion_int` 与 LIS2DW12 的 `irq-gpios` 是同一根线（overlay 里两处都是
 * P1.11），这里用 alias 拿它是为了绕过传感器驱动、自己重配触发方式。 */
static const struct gpio_dt_spec wake_pin =
	GPIO_DT_SPEC_GET(DT_ALIAS(motion_int), gpios);
static const struct device *const dev_uart_modem = DEVICE_DT_GET(DT_NODELABEL(uart1));
static const struct device *const dev_uart_gnss  = DEVICE_DT_GET(DT_NODELABEL(uart0));
static const struct device *const dev_i2c        = DEVICE_DT_GET(DT_NODELABEL(i2c0));

/* 上报线程。栈要够大 —— modem.c 里有 4 KB 的 HEX 缓冲（那个是静态的），
 * 但 AT 命令拼接和 NMEA 解析都在栈上。 */
#define UPLINK_STACK_SIZE 4096
#define UPLINK_PRIORITY   5

K_THREAD_STACK_DEFINE(uplink_stack, UPLINK_STACK_SIZE);
static struct k_thread uplink_thread;

/* 最后一次判定静止的时刻。**只有这一个本地状态** ——
 * 运动状态本身由 motion.c 持有（`motion_current()`），
 * 以前这里另存一份 `volatile bool moving`，那是因为硬件静止事件永不到达、
 * 那份 bool 是唯一能翻的东西。现在 motion.c 的状态机是完整的，
 * 留两份只会分叉。 */
static int64_t last_still_ms;

/* --- 回调 ------------------------------------------------------------------- */

static void on_motion(enum motion_state state, uint16_t mg)
{
	if (state == MOTION_MOVING) {
		char detail[32];

		(void)snprintf(detail, sizeof(detail), "{\"mg\":%u}", mg);
		(void)uplink_queue_event(EV_MOTION, detail);

		/* 动了就把广播打开 —— 用户可能正要开锁 */
		(void)ble_unlock_start();

		/* 车被动了是防盗关心的事件，立刻上报（DESIGN.md §1「防盗感知」） */
		uplink_request_now();
	} else {
		last_still_ms = k_uptime_get();
		(void)uplink_queue_event(EV_STILL, NULL);
	}
}

static void on_unlock_result(bool ok, uint32_t uid)
{
	/* 有人正在动这辆车 —— 即使加速度计没到阈值（人站着按手机，
	 * 车没晃），也不该在这时判静止把广播关掉。成功和被拒都算活动：
	 * 被拒更可能是有人在试，广播反而不该关。 */
	motion_note_activity();

	char detail[32];
	if (ok) {
		(void)snprintf(detail, sizeof(detail), "{\"uid\":%u}", uid);
		(void)uplink_queue_event(EV_UNLOCK_OK, detail);
		/* 验证通过了才驱动锁。unlock.c 已经做完三重校验。 */
		if (lock_unlock() != 0) {
			LOG_ERR("MAC 验过了但锁没动 —— 检查驱动电路");
		}
	} else {
		/* 契约 §5.4：unlock_deny 不含失败原因 ——
		 * §5.2 说了不给攻击者区分信道，上行也不给。 */
		(void)snprintf(detail, sizeof(detail), "{\"uid\":%u}", uid);
		(void)uplink_queue_event(EV_UNLOCK_DENY, detail);
	}
}

static void on_lock_state(bool open)
{
	char detail[32];
	(void)snprintf(detail, sizeof(detail), "{\"locked\":%s}",
		       open ? "false" : "true");
	(void)uplink_queue_event(EV_LOCK_STATE, detail);
}

/* --- System OFF（DESIGN.md §6 第 4 级） ------------------------------------- */

/* 进 System OFF，只留运动唤醒。**不返回。**
 *
 * 五个步骤的顺序都是必需的，逐条说明：
 *
 * 1. **关 radio、输出脚拉到安全电平。** `ble_unlock_shutdown()` 停广播再
 *    `bt_disable()`：radio 也是 EasyDMA master（和第 4 步同一条推理），
 *    而 MPSL 还占着 RTC0/TIMER0/RADIO；`bt_disable()` 底下的 `sdc_disable()`
 *    是同步的，返回即代表 controller 已停。**必须在第 4 步的
 *    `nvstore_flush()` 之前做** —— `SOC_FLASH_NRF_RADIO_SYNC_MPSL` 会让
 *    flash 写等 MPSL timeslot，radio 开着时那次 flush 的最坏延迟不可控。
 *    sleep pinctrl 只在 SUSPEND 时应用，而 GPIO 输出脚不受 pinctrl 管 ——
 *    不拉低的话 GNSS 门控管和分压门控管会一直导通。
 * 2. **确认唤醒脚已回低。** LIS2DW12 默认是 latched 中断（overlay 没设
 *    `drdy-pulsed`），不读清中断源引脚就一直是高。而 level sense 一武装就会
 *    立刻触发 DETECT → `sys_poweroff()` 之后**立即被唤醒 → 空转 → 再关机**
 *    的活锁。所以先等它回低。
 * 3. **把触发方式从边沿改成电平。** 这是整个函数的关键：
 *    LIS2DW12 驱动配的是 `GPIO_INT_EDGE_TO_ACTIVE`
 *    （`lis2dw12_trigger.c` 的 `lis2dw12_init_interrupt` 结尾），走 GPIOTE
 *    IN 事件通道；**而 GPIOTE 在 System OFF 下是断电的**。
 *    能唤醒 System OFF 的只有 GPIO 的 SENSE → DETECT 信号，
 *    而 Zephyr 只在 level 模式下才写 `PIN_CNF[n].SENSE`
 *    （`gpio_nrfx.c` 的 `get_trigger()` 把 LEVEL 映射成
 *    `NRFX_GPIOTE_TRIGGER_HIGH/LOW`，nrfx 侧再落到 `nrfy_gpio_cfg_sense_set`）。
 *    改成 level 时驱动会顺手把之前占的 GPIOTE channel 释放掉。
 * 4. **suspend EasyDMA 外设。** 产品规格书要求进 System OFF 前所有 EasyDMA
 *    传输必须已完成，而 UARTE/TWIM/SAADC 全是 EasyDMA 外设。
 *    `sys_poweroff()` **自己不做这件事**（它只 irq_lock + 写 SYSTEMOFF），
 *    overlay 里那些 `*_sleep` 的 `low-power-enable` 也**只在 SUSPEND 动作时
 *    才被应用**。不 suspend 的后果是引脚继续驱动/继续上拉：接 Air780EP 那路
 *    尤其糟，模组掉电时 TX 的高电平会往模组里灌电流。
 *    **不要 suspend GPIO 端口本身** —— 那会破坏刚武装好的 SENSE。
 * 5. 复位原因位在开机时已经读过并清掉（uplink.c 的 `reset_cause_str`），
 *    这里不用再动。醒来是一次**完整复位**，RESETREAS.OFF 会被置上，
 *    hwinfo 映射成 `RESET_LOW_POWER_WAKE`，下一轮 hello 会报 `rst:"off"`。
 *
 * ⚠ **调试器接着的时候 System OFF 是被仿真的**（产品规格书：Debug Interface
 * mode 下 System OFF 只是停在一个 `WFE` 循环里），电流测出来是毫安级。
 * 实测功耗必须拔掉调试器冷启动，否则会误判「System OFF 没生效」。
 */
static void enter_system_off(void)
{
	LOG_WRN("电压跌破第三阈值，进 System OFF，只留运动唤醒");

	/* 1. 关掉所有耗电的输出 */
	ble_unlock_shutdown();
	(void)gnss_power_off();

	/* 2. 等唤醒脚回低，避免 level sense 一武装就自触发 */
	for (int i = 0; i < 100 && gpio_pin_get_dt(&wake_pin) == 1; i++) {
		k_sleep(K_MSEC(10));
	}
	if (gpio_pin_get_dt(&wake_pin) == 1) {
		LOG_ERR("唤醒脚一直是高（LIS2DW12 中断没清？）—— "
			"关机后会立刻被唤醒");
	}

	/* 3. 边沿 → 电平，这是唯一能从 System OFF 唤醒的形式 */
	int rc = gpio_pin_configure_dt(&wake_pin, GPIO_INPUT);
	if (rc == 0) {
		rc = gpio_pin_interrupt_configure_dt(&wake_pin,
						     GPIO_INT_LEVEL_ACTIVE);
	}
	if (rc != 0) {
		/* 武装失败就别关机 —— 关了就再也醒不过来，只能靠拔电池。 */
		LOG_ERR("武装运动唤醒失败 rc=%d —— **放弃进 System OFF**", rc);
		return;
	}

	/* 4. suspend EasyDMA 外设（不含 GPIO 端口） */
	(void)nvstore_flush();
	const struct device *const suspend_list[] = {
		dev_uart_modem, dev_uart_gnss, dev_i2c,
	};
	for (size_t i = 0; i < ARRAY_SIZE(suspend_list); i++) {
		if (!device_is_ready(suspend_list[i])) {
			continue;
		}
		rc = pm_device_action_run(suspend_list[i],
					  PM_DEVICE_ACTION_SUSPEND);
		if (rc != 0 && rc != -EALREADY && rc != -ENOSYS) {
			LOG_WRN("suspend %s 失败 rc=%d（引脚会继续漏电）",
				suspend_list[i]->name, rc);
		}
	}

	sys_poweroff();   /* 不返回 */
}

/* --- 上报线程 --------------------------------------------------------------- */

static void uplink_thread_fn(void *a, void *b, void *c)
{
	ARG_UNUSED(a);
	ARG_UNUSED(b);
	ARG_UNUSED(c);

	/* 开机先报一次，让服务端知道设备活了（也顺便拿到下行队列） */
	(void)uplink_queue_event(EV_BOOT, NULL);
	(void)uplink_cycle(true);

	while (true) {
		uint32_t interval = nvstore_report_interval();

		/* 欠压第 1 级：上报周期翻 4 倍（§6 第 2 级「降低上报频率」）。
		 * 不改 nvstore 里的配置值 —— 电压回升后要能自己恢复。 */
		if (uplink_batt_level() == 1) {
			interval *= 4;
		}

		/* 等到周期到，或者被 uplink_request_now() 提前叫起来。
		 * 用信号量而不是 k_sleep：运动事件要能打断等待。 */
		bool asked = (k_sem_take(uplink_now_sem(), K_SECONDS(interval)) == 0);

		if (asked) {
			LOG_INF("提前上报（被请求）");
		} else if (!uplink_should_report()) {
			/* 欠压第 2 级：停周期上报，只保留离线开锁和运动触发。
			 * BLE 开锁完全离线（§5.2），不受这条影响。 */
			LOG_INF("欠压等级 %d，跳过这一轮周期上报",
				uplink_batt_level());
			continue;
		}

		/* 每轮都带 GNSS：不带的话轨迹就断了。
		 * 将来要省电可以让纯遥测轮跳过定位，但那要先有实测数据支撑
		 * （R8 阶段，DESIGN.md §10）。 */
		(void)uplink_cycle(true);

		/* 欠压第 3 级：主动进 System OFF。放在上报之后 ——
		 * 先把「我要睡了」这条 lowbatt 事件发出去再睡。 */
		if (uplink_batt_level() >= 3) {
			enter_system_off();
			/* 回到这里说明武装唤醒失败，那就继续跑（见 enter_system_off
			 * 里的说明）—— 醒不过来比多耗一点电严重得多。 */
		}

		/* 静止够久就关广播（防跟踪，不是省电 —— 见 IDLE_AFTER_STILL_MS
		 * 的注释）。放在上报之后：上报期间保持广播开着，
		 * 因为用户可能正好在车边。
		 *
		 * 判 `== MOTION_STILL` 而不是 `!= MOTION_MOVING`：开机后还没
		 * 收到任何事件时状态是 UNKNOWN，那时不该关广播 —— 刚上电大概率
		 * 是有人正在装车或调试。UNKNOWN 会在 STILL_AFTER 秒后自己变成
		 * STILL（motion_init 开机就排了一次超时）。 */
		if (motion_current() == MOTION_STILL && ble_unlock_is_active() &&
		    (k_uptime_get() - last_still_ms) > IDLE_AFTER_STILL_MS) {
			LOG_INF("静止超过 %d 分钟，关广播（不可被扫描发现）",
				IDLE_AFTER_STILL_MS / 60000);
			(void)ble_unlock_stop();
		}

		/* counter 的延迟写窗口是 5 秒，这里主动冲一次 ——
		 * 下一轮之间可能被剪线掉电（没有备份电池，DESIGN.md §6）。 */
		(void)nvstore_flush();
	}
}

/* --- 初始化 ----------------------------------------------------------------- */

int main(void)
{
	LOG_INF("电瓶车定位固件 %s 启动（设备 %s）",
		CONFIG_EBIKE_FW_VERSION, CONFIG_EBIKE_DEVICE_ID);

	/* 顺序有讲究：
	 * crypto 在 unlock 之前（unlock_init 要读密钥并可能用到 PSA）；
	 * nvstore 在 unlock 之前（密钥从 flash 读）；
	 * ble 在 unlock 之后（GATT 写回调会调 unlock_handle_apdu）。 */
	int rc = crypto_init();
	if (rc != 0) {
		/* 没有密码学就没有开锁。这是唯一 fatal 的初始化失败 ——
		 * 其余部件坏了还能降级用，这个坏了核心功能就没了。 */
		LOG_ERR("crypto 初始化失败 rc=%d —— 开锁不可用", rc);
		return rc;
	}

	rc = nvstore_init();
	if (rc != 0) {
		LOG_ERR("nvstore 初始化失败 rc=%d —— 密钥和 counter 无法持久化", rc);
		/* 继续跑：内存里的 counter 仍然能防本次开机内的重放，
		 * 掉电后会退化。比完全不能开锁好。 */
	}

	rc = unlock_init();
	if (rc != 0) {
		LOG_ERR("unlock 初始化失败 rc=%d", rc);
	}
	unlock_set_callback(on_unlock_result);

	rc = lock_init();
	if (rc != 0) {
		LOG_ERR("锁初始化失败 rc=%d —— 验证还能过但锁不会动", rc);
	}
	lock_set_callback(on_lock_state);

	rc = ble_unlock_init();
	if (rc != 0) {
		LOG_ERR("BLE 初始化失败 rc=%d —— 只能用机械钥匙", rc);
	} else {
		/* 开机就开着广播，静止 5 分钟后由上报线程关掉 */
		(void)ble_unlock_start();
		last_still_ms = k_uptime_get();
	}

	rc = motion_init(on_motion);
	if (rc != 0) {
		LOG_ERR("运动检测初始化失败 rc=%d —— 功耗会显著上升，"
			"且收不到「车被动了」的告警", rc);
	}

	rc = battery_init();
	if (rc != 0) {
		LOG_ERR("电池采样初始化失败 rc=%d —— 欠压兜底失效（§6）", rc);
	}

	rc = gnss_init();
	if (rc != 0) {
		LOG_ERR("GNSS 初始化失败 rc=%d —— 只能靠基站定位", rc);
	}

	rc = uplink_init();
	if (rc != 0) {
		LOG_ERR("uplink 初始化失败 rc=%d —— 上报不可用", rc);
	}

	k_thread_create(&uplink_thread, uplink_stack, UPLINK_STACK_SIZE,
			uplink_thread_fn, NULL, NULL, NULL,
			UPLINK_PRIORITY, 0, K_NO_WAIT);
	k_thread_name_set(&uplink_thread, "uplink");

	LOG_INF("初始化完成");
	return 0;
}

/* --- 关于 System OFF ---------------------------------------------------------
 *
 * DESIGN.md §4.2 的 0.40 µA 是 **System OFF** 的数字。本实现**只在欠压第 3 级
 * 用它**（`enter_system_off()`），日常仍然是 System ON + RTC（3.16 µA）+
 * 定时器唤醒。
 *
 * 为什么日常不用 System OFF：
 *
 * 1. System OFF 唤醒等于**复位**，整个初始化要重跑一遍，MQTT 也要重连。
 *    在省电档下（模组本来就关着）代价不大，但会让 uptime、RAM 里的状态、
 *    以及 modem 会话全部丢掉。
 * 2. **真正的功耗地板是 4G 模组，不是主控**（DESIGN.md §4.1b）。
 *    3.16 µA 和 0.40 µA 的差别（2.8 µA）在 0.5~1.5 mA 的模组面前是噪声。
 *    只有在「模组完全关机」的档位上，这 2.8 µA 才占得上比例。
 * 3. 先把主路径调通再抠这 2.8 µA。R8 阶段（§10）才是做双档功耗的时候。
 *
 * 欠压第 3 级是例外：那时的目标不是省 2.8 µA，而是**别把车电池抽空**，
 * 所以宁可付「唤醒 = 复位」的代价。
 *
 * 两处更正（2026-09-02，核实上游源码后）：
 *
 * - 入口是 **`sys_poweroff()`**（`zephyr/sys/poweroff.h`），**不是**
 *   `pm_state_force(PM_STATE_SOFT_OFF)`。后者在 nRF52 上已经没有实现了：
 *   Zephyr v3.5 的迁移文档明说 Nordic nRF 改用 `sys_poweroff`，
 *   而 `soc/.../nrf52/power.c`（里面那个 `pm_state_set`）在 v3.5 就删掉了。
 *   相应地 **`CONFIG_PM` 在 nRF52 上不能开**（`soc/nordic/nrf52/Kconfig` 只
 *   `select HAS_POWEROFF`，没有 `HAS_PM`），要的是 `CONFIG_POWEROFF=y`。
 * - 唤醒源**不是**「GPIOTE PORT 事件」那个 Kconfig：
 *   `CONFIG_GPIO_NRFX_INTERRUPT_DETECT_MODE_PORT` **这个符号根本不存在**
 *   （`drivers/gpio/Kconfig.nrfx` 里只有 `GPIO_NRFX` 和
 *   `GPIO_NRFX_INTERRUPT`），已从 prj.conf 删掉。
 *   真正的机制是**选 level 触发**（见 `enter_system_off()` 第 3 步）：
 *   Zephyr 只在 LEVEL 模式下才写 `PIN_CNF[n].SENSE`，而 SENSE → DETECT
 *   是唯一能唤醒 System OFF 的 GPIO 路径；EDGE 走 GPIOTE IN 事件，
 *   而 GPIOTE 在 System OFF 下断电。
 *   （如果想让 **edge** 也走 SENSE 以省 GPIOTE 的电，那是 devicetree 的
 *   `sense-edge-mask` 属性，不是 Kconfig。本工程不需要。）
 */
```

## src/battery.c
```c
/* 电池电压采样。见 battery.h：门控是功耗预算的前提。 */

#include "battery.h"

#include <errno.h>

#include <zephyr/device.h>
#include <zephyr/drivers/adc.h>
#include <zephyr/drivers/adc/voltage_divider.h>
#include <zephyr/drivers/gpio.h>
#include <zephyr/kernel.h>
#include <zephyr/logging/log.h>
#include <zephyr/sys/util.h>

LOG_MODULE_REGISTER(battery, CONFIG_EBIKE_LOG_LEVEL);

#define VBATT_NODE DT_NODELABEL(vbatt)

static const struct gpio_dt_spec gate =
	GPIO_DT_SPEC_GET(DT_NODELABEL(batt_gate), gpios);

/* 分压比不再手算：voltage_divider_scale_dt() 用 int64 做
 * `mv * full_ohms / output_ohms`，非整数比例也不丢精度。
 * 上一版是 `full/output` 的**整数除**，21:1 恰好整除所以无害，
 * 但换成 19.29:1 之类就会被截断成 19 —— 1.5% 的系统误差，
 * 而且是静默的。 */
static const struct voltage_divider_dt_spec vbatt =
	VOLTAGE_DIVIDER_DT_SPEC_GET(VBATT_NODE);

/* ---- 编译期护栏：分压比配错就不让它编过 --------------------------------------
 *
 * 这一段存在的唯一理由：**配错了是烧芯片，而且物理不可逆**。
 * 上一版 overlay 写的是 1M/1M（2:1），58.8 V 会往 P0.31 灌 29.4 V。
 * 那种错误在代码里看不出来、在日志里看不出来、只在焊完通电的瞬间表现为
 * 一颗死掉的 nRF52840。所以它必须是编译错误，不能是注释里的警告。
 */

/** 电池组的最坏情况电压（毫伏）。48 V 铅酸 = 4 × 12 V，满充按 14.7 V/只算。
 *  ⚠ 换电池规格（60 V / 72 V / 锂电）必须改这里，然后重算 overlay 的分压比。 */
#define PACK_MAX_MV 58800

/** 引脚电压上限（毫伏）。本板 REGOUT0 = 3V3 → VDD = 3.3 V
 *  （nRF52840 PS v1.1 Table 172 推荐工作条件）。
 *
 *  注意**不要**用 Table 173 的绝对最大值 VDD+0.3 = 3.6 V 来算：那是
 *  「短时暴露不永久损坏」的极限，不是可用范围。也**不要**用 ADC 满量程
 *  3.6 V（gain 1/6 × 内部参考 600 mV）—— 那是转换器的上限，
 *  跟引脚能承受多少伏是两件无关的事。 */
#define PIN_MAX_MV 3300

/* 电阻 1% 容差的最坏组合：上臂偏小 + 下臂偏大 → 分压比最小 → 引脚电压最高。
 * 用整数算：ratio_worst = (Rtop*99 + Rbot*101) / (Rbot*101)，
 * 代进去就是 PACK_MAX_MV * (Rbot*101) / (Rtop*99 + Rbot*101)。 */
#define R_TOP_OHMS  (DT_PROP(VBATT_NODE, full_ohms) - DT_PROP(VBATT_NODE, output_ohms))
#define R_BOT_OHMS  DT_PROP(VBATT_NODE, output_ohms)

#define PIN_MV_WORST                                                          \
	((uint64_t)PACK_MAX_MV * ((uint64_t)R_BOT_OHMS * 101) /                \
	 ((uint64_t)R_TOP_OHMS * 99 + (uint64_t)R_BOT_OHMS * 101))

/* ⚠ 断言文本必须是纯 ASCII：GCC 把 `_Static_assert` 的消息按字节转义输出，
 * 中文会变成一串 `\37777777745...`，等于没有提示。实测过。 */
BUILD_ASSERT(PIN_MV_WORST <= PIN_MAX_MV,
	     "vbatt divider ratio too low: pack at full charge exceeds VDD on "
	     "AIN7/P0.31 and will destroy the SoC. Fix full-ohms/output-ohms in "
	     "the vbatt node (boards/*.overlay), or PACK_MAX_MV here.");

/* 源阻抗 = Rtop ‖ Rbot，必须 ≤ 800 kΩ，否则 overlay 里那个 40 µs 采集时间
 * 不成立（PS v1.1 §6.23.10.1 的 tACQ 表）。超了不会烧，但读数会偏低，
 * 而且偏多少取决于引脚电容 —— 是个查不出来的读数误差。 */
#define R_SOURCE_OHMS \
	((uint64_t)R_TOP_OHMS * R_BOT_OHMS / DT_PROP(VBATT_NODE, full_ohms))

BUILD_ASSERT(R_SOURCE_OHMS <= 800000,
	     "vbatt source impedance above 800k: the 40us acquisition time in "
	     "the overlay is not enough and readings will be low. Lower the "
	     "resistor values or raise zephyr,acquisition-time.");

/* 三个欠压阈值必须严格递减，否则中间那级永远不会生效（battery.h 的语义）。 */
BUILD_ASSERT(CONFIG_EBIKE_LOW_VOLT_1 > CONFIG_EBIKE_LOW_VOLT_2 &&
	     CONFIG_EBIKE_LOW_VOLT_2 > CONFIG_EBIKE_LOW_VOLT_3,
	     "need EBIKE_LOW_VOLT_1 > EBIKE_LOW_VOLT_2 > EBIKE_LOW_VOLT_3, "
	     "otherwise the middle level never triggers.");

/* 采样链的**合理性下限**（毫伏）。低于这个值一律当读失败，不当欠压。
 *
 * 为什么需要：整数换算链是 `(raw * 600 * 6 >> 12) * 21`，一个 ADC LSB 是
 * 17.6 mV 引脚电压 → **370 mV 电池电压**。于是 `raw = 2`（满量程的 0.05%）
 * 就换算成 21 mV，直接命中 `battery_low_level()` 的第 3 级 →
 * `enter_system_off()`。而在悬空/断线的高阻输入上读到两个 count 是常态
 * （ADC 自身 ±3% 的 gain 误差、几个 LSB 的偏移误差都在这个量级），不是异常。
 *
 * 不挡的症状：**车电池好好的，车却自己进 System OFF**，摇一下醒来报一轮
 * 又睡回去；上报的 lowbatt 里写着 `v=0.0`。日志和报文都指向「电池空了」，
 * 而真实故障在采样链上 —— 是个查不出来的假欠压。
 *
 * 20 V 的物理依据：整机由 LX-P160 供电，**它的输入下限是 28 V**（§3.1）。
 * 车电池真的低于 28 V 时这块板子根本不在运行，所以「板子在跑 + 采到 20 V
 * 以下」只可能是采样链坏了：线没接、门控 MOS 常闭、分压电阻虚焊。
 *
 * 同型先例：modem.c 的 `MIN_PLAUSIBLE_UTC`（时间也是「不可能的值 = 没拿到」）。
 */
#define MIN_PLAUSIBLE_MV 20000

/* 下限必须低于第三阈值，否则真实的深度欠压会被当成读失败吞掉 ——
 * 那就把 §6 第 4 级（主动 System OFF 保护车电池）整个废了。 */
BUILD_ASSERT(MIN_PLAUSIBLE_MV < CONFIG_EBIKE_LOW_VOLT_3,
	     "MIN_PLAUSIBLE_MV must stay below EBIKE_LOW_VOLT_3, otherwise a "
	     "real deep undervoltage is swallowed as a sampling failure and "
	     "the level-3 System OFF fallback never triggers.");

/* 门控打开后等多久再采。Rs = 448 kΩ 配引脚电容（PS v1.1 给的 CSAMPLE 2.5 pF，
 * 加走线和 ESD 结电容按 20 pF 估）的 RC 常数约 9 µs，给 500 µs 是几十倍余量；
 * 这段时间流的 6 µA 可以忽略。
 *
 * 注意 voltage-divider binding 自带 `power-on-sample-delay-us`（默认 100 µs），
 * 但那条路要走上游的 ADC voltage-divider 驱动；本文件自己开关门控
 * （因为要保证「无论采样成不成功都关」），所以那个属性用不上。 */
#define SETTLE_US 500

static bool ready;

int battery_init(void)
{
	if (!adc_is_ready_dt(&vbatt.port)) {
		LOG_ERR("ADC 未就绪");
		return -ENODEV;
	}
	int rc = adc_channel_setup_dt(&vbatt.port);
	if (rc != 0) {
		LOG_ERR("adc_channel_setup 失败 rc=%d", rc);
		return rc;
	}

	if (!gpio_is_ready_dt(&gate)) {
		LOG_ERR("分压门控 GPIO 未就绪");
		return -ENODEV;
	}
	/* 初始必须是关的 —— 上电就打开会一直流 5.96 µA */
	rc = gpio_pin_configure_dt(&gate, GPIO_OUTPUT_INACTIVE);
	if (rc != 0) {
		return rc;
	}

	ready = true;
	return 0;
}

int battery_read_mv(void)
{
	if (!ready) {
		return -EAGAIN;
	}

	int16_t raw = 0;
	struct adc_sequence seq = {
		.buffer = &raw,
		.buffer_size = sizeof(raw),
	};
	int rc = adc_sequence_init_dt(&vbatt.port, &seq);
	if (rc != 0) {
		return rc;
	}

	rc = gpio_pin_set_dt(&gate, 1);
	if (rc != 0) {
		return rc;
	}
	k_busy_wait(SETTLE_US);

	rc = adc_read_dt(&vbatt.port, &seq);

	/* 无论采样成不成功都要关门控。漏关一次就是永久多 5.96 µA —— 和整机
	 * GPIOTE PORT 的 2.36 µA 同一量级，而这个错误在日志里完全看不见，
	 * 只会在几个月后表现为电池掉得比预期快。 */
	int gate_rc = gpio_pin_set_dt(&gate, 0);
	if (gate_rc != 0) {
		LOG_ERR("关分压门控失败 rc=%d —— 会持续多耗 5.96 µA！", gate_rc);
	}

	if (rc != 0) {
		LOG_ERR("adc_read 失败 rc=%d", rc);
		return rc;
	}

	int32_t mv = raw;
	rc = adc_raw_to_millivolts_dt(&vbatt.port, &mv);
	if (rc != 0) {
		return rc;
	}

	int32_t batt_mv = mv;
	rc = voltage_divider_scale_dt(&vbatt, &batt_mv);
	if (rc != 0) {
		/* full-ohms 缺失才会走到这 —— overlay 里写着，正常不可能 */
		LOG_ERR("分压换算失败 rc=%d（overlay 少了 full-ohms？）", rc);
		return rc;
	}

	/* 合理性下限（见 MIN_PLAUSIBLE_MV）。**返回负数就够了** ——
	 * 两个下游都已经正确处理负数：uplink.c 的 `has_volt = mv > 0` 为假
	 * （`v` 字段整个不发，不是发假的 0.0），`battery_low_level()` 的
	 * `mv <= 0` 把它当读失败而不是欠压。 */
	if (batt_mv < MIN_PLAUSIBLE_MV) {
		LOG_ERR("电池读数 %d mV 低于合理下限 %d mV —— 采样链有问题"
			"（分压线没接？门控 MOS？电阻虚焊？），当读失败处理",
			batt_mv, MIN_PLAUSIBLE_MV);
		return -ENODATA;
	}

	LOG_DBG("电池 %d mV（ADC %d mV，分压 %u/%u）", batt_mv, mv,
		vbatt.full_ohms, vbatt.output_ohms);
	return (int)batt_mv;
}

int battery_low_level(int mv)
{
	if (mv <= 0) {
		return 0;   /* 读失败不当欠压处理 —— 误报会让人白跑一趟 */
	}
	if (mv < CONFIG_EBIKE_LOW_VOLT_3) {
		return 3;   /* 主动进 System OFF，只留运动唤醒（§6 第 4 级） */
	}
	if (mv < CONFIG_EBIKE_LOW_VOLT_2) {
		return 2;   /* 停周期上报，只保留离线开锁（§6 第 3 级） */
	}
	if (mv < CONFIG_EBIKE_LOW_VOLT_1) {
		return 1;   /* 降低上报频率并上报状态（§6 第 2 级） */
	}
	return 0;
}
```

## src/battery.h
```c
/*
 * 电池电压采样 —— 必须门控（DESIGN.md §3.6）。
 *
 * 分压器是 21:1（上臂 4.7M+4.7M 串联，下臂 470k），常通时对 58.8 V 是
 * **5.96 µA**，和 nRF52840 自己 GPIOTE PORT 的 2.36 µA 同一量级。
 * 所以分压器低端串一个 MOSFET，只在采样的瞬间打开。
 *
 * 21:1 这个比例是三个上限定的（overlay 的 vbatt 节点有完整推导 + battery.c
 * 有对应的 BUILD_ASSERT）：引脚 ≤ VDD 3.3 V、源阻抗 ≤ 800 kΩ、
 * 单只电阻耐压。**换电池规格要改 battery.c 的 `PACK_MAX_MV` 并重算比例。**
 */

#ifndef EBIKE_BATTERY_H
#define EBIKE_BATTERY_H

#include <stdint.h>

int battery_init(void);

/* 采一次电压，毫伏。返回负数表示失败。
 * 里面会开门控 → 等稳定 → 采 → 关门控，整个过程约 1 ms。 */
int battery_read_mv(void);

/* 欠压等级（DESIGN.md §6 的四级软件兜底）：
 *   0 = 正常，或读失败（读失败不当欠压 —— 误报会让人白跑一趟）
 *   1 = 跨过第一阈值：降低上报频率，并把状态报上去让 HA 能看到
 *   2 = 跨过第二阈值：停止周期上报，只保留手机 BLE 开锁（那条路完全离线）
 *   3 = 跨过第三阈值：主动进 System OFF，只留运动唤醒
 *
 * 这一路保护的是**车电池**别被抽空，不保护设备自己 —— 设备没有独立电源（§4.4）。
 */
int battery_low_level(int mv);

#endif /* EBIKE_BATTERY_H */
```

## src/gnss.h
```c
/*
 * GNSS：ATGM336H-5N，NMEA over UART 9600。
 *
 * 支持北斗（NEO-7M 在协议层没有北斗且已 EOL，所以选它 —— DESIGN.md §1）。
 *
 * 电源门控：GNSS 模块工作时是几十 mA 量级，不能常开。
 * 采一次位置的流程是「上电 → 等定位 → 读 → 断电」，冷启动可能要几十秒，
 * 所以 gnss_fix() 是阻塞的，必须在自己的线程里调，不能在中断或 GATT 回调里。
 */

#ifndef EBIKE_GNSS_H
#define EBIKE_GNSS_H

#include <stdbool.h>
#include <stdint.h>

struct gnss_fix {
	double lat;
	double lon;
	float hdop;      /* 用来估精度圈 */
	float acc_m;     /* 由 hdop 估出来的水平精度，米 */
	float speed_ms;
	int16_t heading;
	uint8_t sats;
	uint32_t utc;    /* NMEA 里的 UTC 秒；0 = 无效 */
	bool valid;
};

int gnss_init(void);

/* 开电、等定位、关电。timeout_s 内没定上返回 -ETIMEDOUT。
 * **阻塞**，别在回调里调。 */
int gnss_fix(struct gnss_fix *out, uint32_t timeout_s);

/* 强制断电 —— 进休眠前调，防止上一次采样异常退出后电源没关。 */
int gnss_power_off(void);

#endif /* EBIKE_GNSS_H */
```
